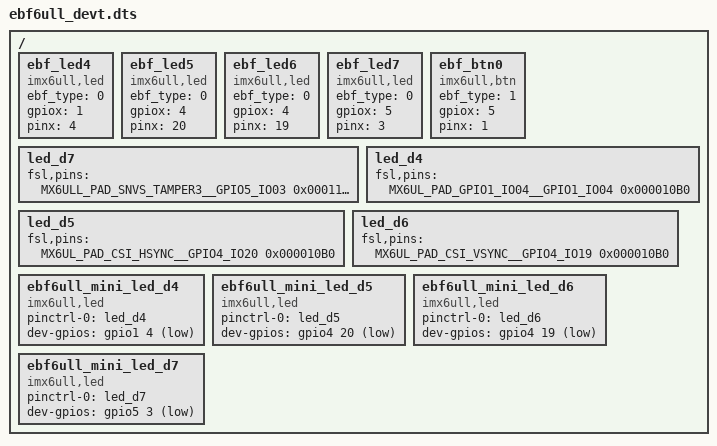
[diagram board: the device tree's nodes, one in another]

/************************************************
 * @file ebf6ull_devt.dts
 * @author Trisuborn (ttowfive@gmail.com)
 * @brief device tree for ebf6ull mini board.
 * @version 0.1
 * @date 2020-10-25
 * 
 * @copyright Copyright (c) 2020
 * 
 ************************************************/

#define EBF6ULL_LED_COMPATIBLE "imx6ull,led"

/* 根节点 */
/ {
    /* no pinctrl */
    ebf_led4 {
        compatible = "imx6ull,led";
        ebf_type = <0>;
        gpiox = <1>;
        pinx  = <4>;
    };
    ebf_led5 {
        compatible = "imx6ull,led";
        ebf_type = <0>;
        gpiox = <4>;
        pinx  = <20>;
    };
    ebf_led6 {
        compatible = "imx6ull,led";
        ebf_type = <0>;
        gpiox = <4>;
        pinx  = <19>;
    };
    ebf_led7 {
        compatible = "imx6ull,led";
        ebf_type = <0>;
        gpiox = <5>;
        pinx  = <3>;
    };
    ebf_btn0 {
        compatible = "imx6ull,btn";
        ebf_type = <1>;
        gpiox = <5>;
        pinx  = <1>;
    };
    
    /* use pinctrl */
    /* snvs */
    led_d7: led_d7 {        /*!< Function assigned for the core: Cortex-A7[ca7] */
        fsl,pins = <
            MX6ULL_PAD_SNVS_TAMPER3__GPIO5_IO03        0x000110A0
        >;
    };
    /* normal */
    led_d4: led_d4 {                /*!< Function assigned for the core: Cortex-A7[ca7] */
        fsl,pins = <
            MX6UL_PAD_GPIO1_IO04__GPIO1_IO04           0x000010B0
        >;
    };
    led_d5: led_d5 {                /*!< Function assigned for the core: Cortex-A7[ca7] */
        fsl,pins = <
            MX6UL_PAD_CSI_HSYNC__GPIO4_IO20            0x000010B0
        >;
    };
    led_d6: led_d6 {                /*!< Function assigned for the core: Cortex-A7[ca7] */
        fsl,pins = <
            MX6UL_PAD_CSI_VSYNC__GPIO4_IO19            0x000010B0
        >;
    };


    ebf6ull_mini_led_d4 {
        compatible = "imx6ull,led";
        pinctrl-names = "default";
        pinctrl-0 = <&led_d4>;
        dev-gpios = <&gpio1 4 GPIO_ACTIVE_LOW>;
    };
    ebf6ull_mini_led_d5 {
        compatible = "imx6ull,led";
        pinctrl-names = "default";
        pinctrl-0 = <&led_d5>;
        dev-gpios = <&gpio4 20 GPIO_ACTIVE_LOW>;
    };
    ebf6ull_mini_led_d6 {
        compatible = "imx6ull,led";
        pinctrl-names = "default";
        pinctrl-0 = <&led_d6>;
        dev-gpios = <&gpio4 19 GPIO_ACTIVE_LOW>;
    };
    ebf6ull_mini_led_d7 {
        compatible = "imx6ull,led";
        pinctrl-names = "default";
        pinctrl-0 = <&led_d7>;
        dev-gpios = <&gpio5 3 GPIO_ACTIVE_LOW>;
    };

};
